# MU3E_LVDS_RX_CONTROLLER_PRO register map
Vendor: Mu3e; Series: MU3E_FPGA_IP; File version: 26.2.1.0506
CMSIS-SVD description of the current SystemVerilog mu3e_lvds_controller CSR window for N_LANE=9, N_ENGINE=1, ROUTING_TOPOLOGY=1, and AVMM_ADDR_W=10. This map matches mu3e_lvds_controller.sv version 26.2.1: UID/META at words 0/1, capability at word 2, global control words at 3..10, lane selector at word 16, and the selected-lane counter snapshot window at words 17..26. BaseAddress is 0 because this file describes the relative IP CSR aperture; system integration supplies the live SC-hub or JTAG base address.
Registers are 32-bit, read-only, reset 0x0 unless marked. A register's access mark holds for its fields unless they carry their own. Offsets are from the block's base; lines under a group give offsets from that group; [hi:lo] are bit positions; {n}, {i} and the like mark numbered series; 'fields as' and 'values as' point back to an identical list; <NAME> marks a mode.

## Memory map
0x00000000 LVDS_RX_CONTROLLER_PRO_CSR size 0x1000 — Relative CSR aperture for the current SystemVerilog LVDS receive controller.

## LVDS_RX_CONTROLLER_PRO_CSR — Relative CSR aperture for the current SystemVerilog LVDS receive controller.
Base 0x00000000
0x00 UID reset 0x4C564453 — Software-visible LVDS controller UID. Default ASCII "LVDS" (0x4C564453).
  [31:0] value — Compile-time or integration-time LVDS UID word.
0x04 META rw — Read-multiplexed metadata word. Write page[1:0] before reading back: 0=VERSION, 1=VERSION_DATE, 2=VERSION_GIT, 3=INSTANCE_ID.
  [1:0] page — Selects the metadata read page.
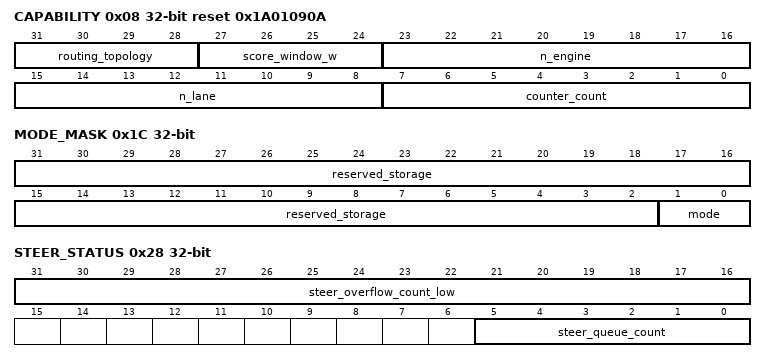
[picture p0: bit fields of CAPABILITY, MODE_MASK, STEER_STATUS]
0x08 CAPABILITY reset 0x1A01090A — Packed capability word for the compiled lane/engine/routing profile.
  [31:28] routing_topology — Compiled routing topology selector.
  [27:24] score_window_w — Score-window width used by the engine steering score saturators.
  [23:16] n_engine — Number of shared decode engines after RTL parameter clamping.
  [15:8] n_lane — Number of active LVDS lanes after RTL parameter clamping.
  [7:0] counter_count — Number of per-lane counters exposed through the selected-lane counter window.
0x0C SYNC_PATTERN rw reset 0xFA — Training/control symbol accepted as the lane synchronization pattern. Writes are accepted only for RTL-recognized K28.5/K28.0/K23.7 encodings.
  [9:0] pattern — 10-bit synchronization symbol.
0x10 LANE_GO rw reset 0x1FF — Per-lane enable mask, clipped by the compiled active-lane mask.
  [31:0] lane_mask — One bit per physical LVDS lane.
0x14 DPA_HOLD rw — Per-lane DPA hold request mask, clipped by the compiled active-lane mask.
  [31:0] lane_mask — One bit per physical LVDS lane.
0x18 SOFT_RESET rw — Per-lane soft-reset request latch. Writing 1 requests a lane soft reset; RTL clears the bit after the hold interval completes.
  [31:0] lane_mask — One bit per physical LVDS lane.
0x1C MODE_MASK rw — Global two-bit lane mode in the current RTL. The full word is stored, but lane_mode() currently consumes bits [1:0].
  [31:2] reserved_storage — Stored by RTL for future per-lane mode expansion; currently not decoded by lane_mode().
  [1:0] mode — 0=bitslipping, 1=adapting, 2=autoing.
0x20 SCORE_ACCEPT rw reset 0x8 — Engine steering accept threshold, clamped by the RTL score window.
  [15:0] threshold — Accept threshold.
0x24 SCORE_REJECT rw reset 0x2 — Engine steering reject threshold, clamped not to exceed SCORE_ACCEPT.
  [15:0] threshold — Reject threshold.
0x28 STEER_STATUS — Snapshot status from the data-clock steering queue. This read may wait while the control clock requests the data-clock snapshot.
  [31:16] steer_overflow_count_low — Low 16 bits of the saturating steering-queue overflow counter.
  [5:0] steer_queue_count — Current queued engine-steering decisions.
0x40 LANE_SELECT rw — Selected lane for the counter snapshot window. Writes above the last active lane clamp to the last active lane.
  [5:0] lane — Zero-based lane index for counter snapshot reads.
0x44 CODE_VIOLATIONS — Illegal or unexpected 8b/10b symbol events observed on the selected lane. The lane is selected by LANE_SELECT and the value is returned through the RTL snapshot path.
  [31:0] value — Selected-lane saturating counter value.
0x48 DISP_VIOLATIONS — Disparity violation events observed on the selected lane. The lane is selected by LANE_SELECT and the value is returned through the RTL snapshot path.
  [31:0] value — Selected-lane saturating counter value.
0x4C COMMA_LOSSES — Selected-lane comma/sync-pattern loss events. The lane is selected by LANE_SELECT and the value is returned through the RTL snapshot path.
  [31:0] value — Selected-lane saturating counter value.
0x50 BITSLIP_EVENTS — Selected-lane bitslip control events. The lane is selected by LANE_SELECT and the value is returned through the RTL snapshot path.
  [31:0] value — Selected-lane saturating counter value.
0x54 DPA_UNLOCKS — Selected-lane DPA unlock events. The lane is selected by LANE_SELECT and the value is returned through the RTL snapshot path.
  [31:0] value — Selected-lane saturating counter value.
0x58 REALIGNS — Selected-lane realignment events. The lane is selected by LANE_SELECT and the value is returned through the RTL snapshot path.
  [31:0] value — Selected-lane saturating counter value.
0x5C SCORE_CHANGES — Selected-lane engine-score change events. The lane is selected by LANE_SELECT and the value is returned through the RTL snapshot path.
  [31:0] value — Selected-lane saturating counter value.
0x60 ENGINE_STEER — Selected-lane engine steering decisions. The lane is selected by LANE_SELECT and the value is returned through the RTL snapshot path.
  [31:0] value — Selected-lane saturating counter value.
0x64 SOFT_RESETS — Selected-lane soft-reset completions. The lane is selected by LANE_SELECT and the value is returned through the RTL snapshot path.
  [31:0] value — Selected-lane saturating counter value.
0x68 UPTIME — Selected-lane uptime counter in data-clock cycles. The lane is selected by LANE_SELECT and the value is returned through the RTL snapshot path.
  [31:0] value — Selected-lane saturating counter value.
